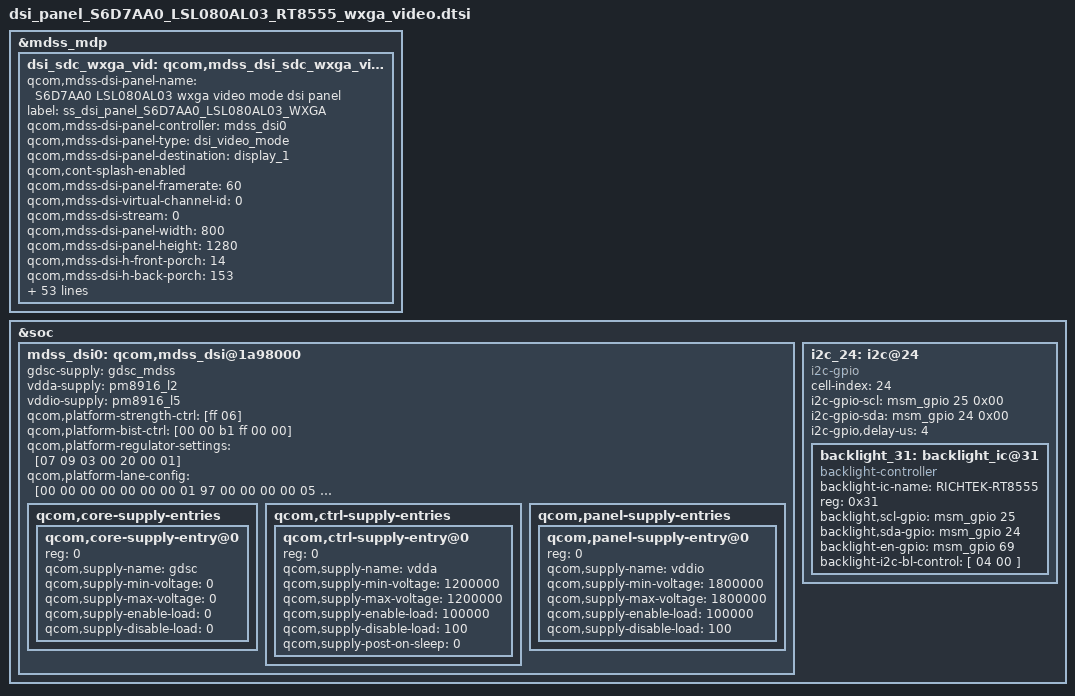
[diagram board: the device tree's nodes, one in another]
/* Copyright (c) 2013, The Linux Foundation. All rights reserved.
 *
 * This program is free software; you can redistribute it and/or modify
 * it under the terms of the GNU General Public License version 2 and
 * only version 2 as published by the Free Software Foundation.
 *
 * This program is distributed in the hope that it will be useful,
 * but WITHOUT ANY WARRANTY; without even the implied warranty of
 * MERCHANTABILITY or FITNESS FOR A PARTICULAR PURPOSE.  See the
 * GNU General Public License for more details.
 */

/*---------------------------------------------------------------------------
 * This file is autogenerated file using gcdb parser. Please do not edit it.
 * Update input XML file to add a new entry or update variable in this file
 * VERSION = "1.0"
 *---------------------------------------------------------------------------*/
&mdss_mdp {
	dsi_sdc_wxga_vid: qcom,mdss_dsi_sdc_wxga_video {
		qcom,mdss-dsi-panel-name = "S6D7AA0 LSL080AL03 wxga video mode dsi panel";
		label = "ss_dsi_panel_S6D7AA0_LSL080AL03_WXGA";
		qcom,mdss-dsi-panel-controller = <&mdss_dsi0>;
		qcom,mdss-dsi-panel-type = "dsi_video_mode";
		qcom,mdss-dsi-panel-destination = "display_1";
		qcom,cont-splash-enabled;
		qcom,mdss-dsi-panel-framerate = <60>;
		qcom,mdss-dsi-virtual-channel-id = <0>;
		qcom,mdss-dsi-stream = <0>;
		qcom,mdss-dsi-panel-width = <800>;
		qcom,mdss-dsi-panel-height = <1280>;
		qcom,mdss-dsi-h-front-porch = <14>;
		qcom,mdss-dsi-h-back-porch = <153>;
		qcom,mdss-dsi-h-pulse-width = <16>;
		qcom,mdss-dsi-h-sync-skew = <0>;
		qcom,mdss-dsi-v-back-porch = <4>;
		qcom,mdss-dsi-v-front-porch = <4>;
		qcom,mdss-dsi-v-pulse-width = <4>;
		qcom,mdss-dsi-h-left-border = <0>;
		qcom,mdss-dsi-h-right-border = <0>;
		qcom,mdss-dsi-v-top-border = <0>;
		qcom,mdss-dsi-v-bottom-border = <0>;
		qcom,mdss-dsi-bpp = <24>;
		qcom,mdss-dsi-underflow-color = <0xff>;
		qcom,mdss-dsi-border-color = <0>;
		qcom,mdss-dsi-on-command = [
					39 01 00 00 01 00 03 F0 5A 5A
					39 01 00 00 00 00 03 F1 5A 5A
					39 01 00 00 00 00 03 FC A5 A5
					39 01 00 00 01 00 03 D0 00 10
					39 01 00 00 01 00 02 B6 10
					39 01 00 00 01 00 04 C3 40 00 08
					39 01 00 00 01 00 04 BC 00 4E A2
					39 01 00 00 01 00 05 FD 16 10 11 23
					39 01 00 00 01 00 07 FE 00 02 03 21 00 70
					39 01 00 00 05 00 02 53 2C
					39 01 00 00 01 00 02 51 FF
					39 01 00 00 01 00 02 36 04
					05 01 00 00 78 00 02 11 00
					39 01 00 00 01 00 02 36 00
					39 01 00 00 01 00 03 F0 A5 A5
					39 01 00 00 01 00 03 F1 A5 A5
					39 01 00 00 01 00 03 FC 5A 5A
					05 01 00 00 01 00 02 29 00
		];
		qcom,mdss-dsi-off-command = [05 01 00 00 40 00 02 28 00
					05 01 00 00 0A 00 02 10 00
		];
		qcom,mdss-dsi-on-command-state = "dsi_lp_mode";
		qcom,mdss-dsi-off-command-state = "dsi_hs_mode";
		qcom,mdss-dsi-h-sync-pulse = <0>;
		qcom,mdss-dsi-bllp-eof-power-mode;
		qcom,mdss-dsi-bllp-power-mode;
		qcom,mdss-dsi-lane-0-state;
		qcom,mdss-dsi-lane-1-state;
		qcom,mdss-dsi-lane-2-state;
		qcom,mdss-dsi-lane-3-state;
		qcom,mdss-dsi-panel-timings = [66 2B 0D 00 37 3D 12 2F 17 03 04 00];
		qcom,mdss-dsi-t-clk-post = <0x04>;
		qcom,mdss-dsi-t-clk-pre = <0x16>;
		qcom,mdss-dsi-bl-min-level = <1>;
		qcom,mdss-dsi-bl-max-level = <255>;
		qcom,mdss-dsi-dma-trigger = "trigger_sw";
		qcom,mdss-dsi-mdp-trigger = "none";
		qcom,esd-check-enabled;
		qcom,mdss-dsi-panel-status-check-mode="reg_read_irq";
		qcom,mdss-dsi-panel-status-value = <1>;
		qcom,mdss-dsi-panel-status-irq-trigger="rising";
		qcom,mdss-dsi-reset-sequence = <1 20>, <0 20>, <1 20>;
		qcom,mdss-pan-physical-width-dimension = <108>;
		qcom,mdss-pan-physical-height-dimension = <172>;
		qcom,mdss-dsi-lp11-init;
		qcom,mdss-dsi-init-delay-us = <20000>;
		qcom,mdss-dsi-force-clk-lane-hs = <1>;
		samsung,tft-common-support;
		samsung,tft_pwm_tx_cmds_revA=[
			39 01 00 00 00 00 02 51 FF/*First command should be PWM duty change command*/
		];
		samsung,cabc_on_tx_cmds_revA = [
			39 01 00 00 00 00 02 55 01
		];
		samsung,cabc_off_tx_cmds_revA = [
			39 01 00 00 00 00 02 55 00
		];
		/*
		* ************************************************************************************************************************
		* Scaled level to index mappings
		* ************************************************************************************************************************
		*/
		samsung,scaled_level_map_table_revA = <
		/*<idx>	  <from>  <till> <scaled_level> */
			0	0	10	2
			1	11	11	3
			2	12	12	4
			3	13	13	5
			4	14	14	6
			5	15	15	7
			6	16	16	8
			7	17	17	9
			8	18	18	10
			9	19	19	11
			10	20	21	12
			11	22	22	13
			12	23	23	14
			13	24	24	15
			14	25	25	16
			15	26	27	17
			16	28	28	18
			17	29	29	19
			18	30	30	20
			19	31	31	21
			20	32	33	22
			21	34	34	23
			22	35	35	24
			23	36	36	25
			24	37	37	26
			25	38	38	27
			26	39	40	28
			27	41	41	29
			28	42	42	30
			29	43	43	31
			30	44	44	32
			31	45	46	33
			32	47	47	34
			33	48	48	35
			34	49	49	36
			35	50	50	37
			36	51	51	38
			37	52	53	39
			38	54	54	40
			39	55	55	41
			40	56	56	42
			41	57	57	43
			42	58	59	44
			43	60	60	45
			44	61	61	46
			45	62	62	47
			46	63	63	48
			47	64	64	49
			48	65	66	50
			49	67	67	51
			50	68	68	52
			51	69	69	53
			52	70	70	54
			53	71	72	55
			54	73	73	56
			55	74	74	57
			56	75	75	58
			57	76	76	59
			58	77	77	60
			59	78	79	61
			60	80	80	62
			61	81	81	63
			62	82	82	64
			63	83	83	65
			64	84	85	66
			65	86	86	67
			66	87	87	68
			67	88	88	69
			68	89	89	70
			69	90	90	71
			70	91	92	72
			71	93	93	73
			72	94	94	74
			73	95	95	75
			74	96	96	76
			75	97	98	77
			76	99	99	78
			77	100	100	79
			78	101	101	80
			79	102	102	81
			80	103	103	82
			81	104	105	83
			82	106	106	84
			83	107	107	85
			84	108	108	86
			85	109	109	87
			86	110	111	88
			87	112	112	89
			88	113	113	90
			89	114	114	91
			90	115	115	92
			91	116	116	93
			92	117	118	94
			93	119	119	95
			94	120	120	96
			95	121	121	97
			96	122	122	98
			97	123	124	99
			98	125	125	100
			99	126	126	101
			100	127	127	102
			101	128	128	103
			102	129	129	104
			103	130	131	105
			104	132	132	106
			105	133	133	107
			106	134	134	108
			107	135	135	109
			108	136	137	110
			109	138	138	111
			110	139	139	112
			111	140	140	113
			112	141	141	114
			113	142	143	116
			114	144	144	117
			115	145	145	118
			116	146	146	119
			117	147	147	120
			118	148	148	122
			119	149	149	123
			120	150	150	124
			121	151	151	125
			122	152	152	127
			123	153	153	128
			124	154	154	129
			125	155	155	130
			126	156	156	132
			127	157	157	133
			128	158	158	134
			129	159	159	135
			130	160	160	137
			131	161	161	138
			132	162	162	139
			133	163	163	140
			134	164	164	142
			135	165	165	143
			136	166	166	144
			137	167	167	145
			138	168	168	147
			139	169	169	148
			140	170	170	149
			141	171	171	150
			142	172	172	151
			143	173	173	153
			144	174	174	154
			145	175	175	155
			146	176	176	156
			147	177	177	158
			148	178	178	159
			149	179	179	160
			150	180	180	161
			151	181	181	163
			152	182	182	164
			153	183	183	165
			154	184	184	166
			155	185	185	168
			156	186	186	169
			157	187	187	170
			158	188	188	171
			159	189	189	173
			160	190	190	174
			161	191	191	175
			162	192	192	176
			163	193	193	178
			164	194	194	179
			165	195	195	180
			166	196	196	181
			167	197	197	183
			168	198	198	184
			169	199	199	185
			170	200	200	186
			171	201	201	187
			172	202	202	189
			173	203	203	190
			174	204	204	191
			175	205	205	192
			176	206	206	194
			177	207	207	195
			178	208	208	196
			179	209	209	197
			180	210	210	199
			181	211	211	200
			182	212	212	201
			183	213	213	202
			184	214	214	204
			185	215	215	205
			186	216	216	206
			187	217	217	207
			188	218	218	209
			189	219	219	210
			190	220	220	211
			191	221	221	212
			192	222	222	214
			193	223	223	215
			194	224	224	216
			195	225	225	217
			196	226	226	219
			197	227	227	220
			198	228	228	221
			199	229	229	222
			200	230	230	223
			201	231	231	225
			202	232	232	226
			203	233	233	227
			204	234	234	228
			205	235	235	230
			206	236	236	231
			207	237	237	232
			208	238	238	233
			209	239	239	235
			210	240	240	236
			211	241	241	237
			212	242	242	238
			213	243	243	240
			214	244	244	241
			215	245	245	242
			216	246	246	243
			217	247	247	245
			218	248	248	246
			219	249	249	247
			220	250	250	248
			221	251	251	250
			222	252	252	251
			223	253	253	252
			224	254	254	253
			225	255	255	255
		>;
	};
};
&soc {
	mdss_dsi0: qcom,mdss_dsi@1a98000 {
		gdsc-supply = <&gdsc_mdss>;
		vdda-supply = <&pm8916_l2>;
		vddio-supply = <&pm8916_l5>;
		qcom,platform-strength-ctrl = [ff 06];
		qcom,platform-bist-ctrl = [00 00 b1 ff 00 00];
		qcom,platform-regulator-settings = [07 09 03 00 20 00 01];
		qcom,platform-lane-config = [00 00 00 00 00 00 00 01 97
			00 00 00 00 05 00 00 01 97
			00 00 00 00 0a 00 00 01 97
			00 00 00 00 0f 00 00 01 97
			00 c0 00 00 00 00 00 01 bb];
		qcom,core-supply-entries {
			#address-cells = <1>;
			#size-cells = <0>;

			qcom,core-supply-entry@0 {
				reg = <0>;
				qcom,supply-name = "gdsc";
				qcom,supply-min-voltage = <0>;
				qcom,supply-max-voltage = <0>;
				qcom,supply-enable-load = <0>;
				qcom,supply-disable-load = <0>;
			};
		};
		qcom,ctrl-supply-entries {
			#address-cells = <1>;
			#size-cells = <0>;

			qcom,ctrl-supply-entry@0 {
				reg = <0>;
				qcom,supply-name = "vdda";
				qcom,supply-min-voltage = <1200000>;
				qcom,supply-max-voltage = <1200000>;
				qcom,supply-enable-load = <100000>;
				qcom,supply-disable-load = <100>;
				qcom,supply-post-on-sleep = <0>;
			};
		};
		qcom,panel-supply-entries {
			#address-cells = <1>;
			#size-cells = <0>;


			qcom,panel-supply-entry@0 {
				reg = <0>;
				qcom,supply-name = "vddio";
				qcom,supply-min-voltage = <1800000>;
				qcom,supply-max-voltage = <1800000>;
				qcom,supply-enable-load = <100000>;
				qcom,supply-disable-load = <100>;
			};
		};
	};
	i2c_24: i2c@24 {
		cell-index = <24>;
		compatible = "i2c-gpio";
		i2c-gpio-scl = <&msm_gpio 25  0x00>; /*scl gpio*/
		i2c-gpio-sda = <&msm_gpio 24 0x00>;  /*sda gpio*/
		i2c-gpio,delay-us = <4>;
		backlight_31: backlight_ic@31 {
			compatible = "backlight-controller";
			backlight-ic-name = "RICHTEK-RT8555";
			reg = <0x31>;
			backlight,scl-gpio = <&msm_gpio 25 0x00>;
			backlight,sda-gpio = <&msm_gpio 24 0x00>;
			backlight-en-gpio = <&msm_gpio 69 0x00>;
			backlight-i2c-bl-control = [
					04 00
			];
		};
	};
};
